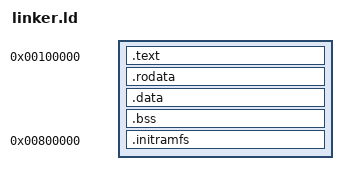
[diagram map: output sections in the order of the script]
ENTRY(_start)

SECTIONS
{
    . = 1M;

    .text : ALIGN(4K)
    {
        *(.multiboot)
        *(.text)
    }

    .rodata : ALIGN(4K)
    {
        *(.rodata)
    }

    .data : ALIGN(4K)
    {
        *(.data)
    }

    .bss : ALIGN(4K)
    {
        *(COMMON)
        *(.bss)
    }

    /* Embedded filesystem image. The ELF loader reads /bin/init from here. */
    . = 8M;
    .initramfs : ALIGN(4K)
    {
        __initramfs_start = .;
        KEEP(*(.initramfs))
        __initramfs_end = .;
    }

    /DISCARD/ :
    {
        *(.comment)
        *(.eh_frame)
        *(.note.GNU-stack)
    }
}
